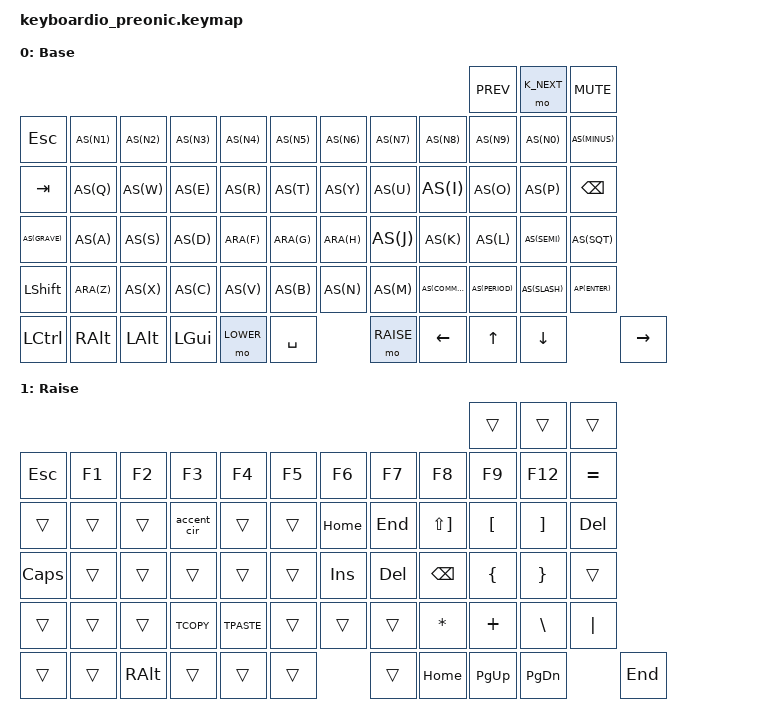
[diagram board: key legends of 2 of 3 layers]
/*
 * Copyright (c) 2022 Pete Johanson
 *
 * SPDX-License-Identifier: MIT
 */

#include <behaviors.dtsi>
#include <dt-bindings/zmk/keys.h>
#include <dt-bindings/zmk/bt.h>
#include <dt-bindings/zmk/outputs.h>


#define LOWER 2
#define RAISE 1


// Using layer taps on thumbs, having quick tap as well helps w/ repeating space/backspace
&lt { quick_tap_ms = <200>; };

// Convenience macro to make the Bluetooth commands shorter
#define BT(n) BT_SEL n

// Hyper key: all the modifiers
#define HYPER LC(LS(LA(LGUI)))
// Define copy paster in terminal
#define TCOPY LC(LS(C))
#define TPASTE LC(LS(V))

// define autoshift feature
#define AS(keycode) &as LS(keycode) keycode
#define ARA(keycode) &as RA(keycode) keycode
#define AP(keycode) &as PIPE keycode
/ {
    chosen {
        // Valid choices: [ &mit_layout, &ortho_layout ]
        zmk,physical-layout = &mit_layout;
    };


    behaviors {
            as: auto_shift {
                compatible = "zmk,behavior-hold-tap";
                label = "AUTO_SHIFT";
                #binding-cells = <2>;
                tapping_term_ms = <170>;
                quick_tap_ms = <0>;
                flavor = "tap-preferred";
                bindings = <&kp>, <&kp>;
            };

        };

    macros {
        accent_cir: accent_cir {
            compatible = "zmk,behavior-macro";
            #binding-cells = <0>;
            bindings
                = <&macro_tap &kp RA(N6) &kp e>
                ;
        };
    };




    keymap {
        compatible = "zmk,keymap";

        base_layer {
            label = "Base";
            bindings = <
                                                                                                             &kp K_PREV    &mo K_NEXT      &kp C_MUTE

 &kp ESC   AS(N1)      AS(N2)      AS(N3)      AS(N4)      AS(N5)      AS(N6)      AS(N7)      AS(N8)      AS(N9)      AS(N0)      AS(MINUS)
 &kp TAB     AS(Q)       AS(W)       AS(E)       AS(R)       AS(T)       AS(Y)       AS(U)       AS(I)       AS(O)       AS(P)       &kp BKSP
 AS(GRAVE)     AS(A)       AS(S)       AS(D)       ARA(F)       ARA(G)       ARA(H)       AS(J)       AS(K)      AS(L)       AS(SEMI)    AS(SQT)
 &kp LSHFT   ARA(Z)       AS(X)       AS(C)       AS(V)       AS(B)        AS(N)       AS(M)       AS(COMMA)   AS(PERIOD)  AS(SLASH)   AP(ENTER)
 &kp LCTRL   &kp RALT   &kp LALT    &kp LGUI    &mo LOWER         &kp SPACE         &mo RAISE   &kp LEFT    &kp UP    &kp DOWN      &kp RIGHT

            >;
            sensor-bindings = <&inc_dec_kp C_VOLUME_UP C_VOLUME_DOWN>;            
        };

        raise_layer {
            label = "Raise";
            bindings = <
                                                                                                               &trans     &trans     &trans

 &kp ESC     &kp F1      &kp F2      &kp F3      &kp F4      &kp F5      &kp F6      &kp F7       &kp F8       &kp F9     &kp F12    &kp EQUAL
 &trans      &trans      &trans      &accent_cir      &trans      &trans      &kp HOME    &kp END &kp LS(RBKT) &kp LBKT   &kp RBKT   &kp DEL
 &kp CAPS    &trans      &trans      &trans      &trans      &trans      &kp INS    &kp DEL     &kp BSPC       &kp LEFT_BRACE  &kp RIGHT_BRACE     &trans
 &trans      &trans      &trans      &kp TCOPY    &kp TPASTE      &trans      &trans      &trans       &kp STAR       &kp PLUS     &kp BACKSLASH     &kp PIPE
 &trans      &trans      &kp RALT    &trans      &trans            &trans            &trans       &kp HOME       &kp PG_UP     &kp PG_DN     &kp END

            >;
            sensor-bindings = <&inc_dec_kp C_VOLUME_UP C_VOLUME_DOWN>;
        };

        func_layer {
            label = "Function";
            bindings = <
                                                                                                             &trans      &trans      &trans

 &out OUT_TOG &kp F1   &kp F2   &kp F3   &kp F4   &kp F5   &kp F6      &kp F7      &kp F8     &kp F9      &kp F10      &kp F11
 &trans       &bt BT(0)   &bt BT(1)   &bt BT(2)   &bt BT(3)   &bt BT(4)      &trans      &trans      &trans     &trans      &trans      &kp F12
 &trans       &trans      &trans      &trans      &trans      &trans      &trans      &trans      &trans     &trans      &trans      &trans
 &trans       &trans      &trans      &kp TCOPY    &kp TPASTE      &trans      &trans      &trans      &trans     &trans      &trans      &trans
 &bootloader  &trans      &trans      &trans      &studio_unlock    &trans            &bt BT_CLR       &kp HOME       &kp PG_UP     &kp PG_DN     &kp END

            >;
            sensor-bindings = <&inc_dec_kp C_VOLUME_UP C_VOLUME_DOWN>;
        };
    };
};
